# ARMv8M-Baseline register map
Registers are read-only, no defined reset value unless marked. A register's access mark holds for its fields unless they carry their own. Offsets are from the block's base; [hi:lo] are bit positions; {n}, {i} and the like mark numbered series.

## DIB — Debug Identification Block
Base 0xE000EFB0
0x00 DLAR wo — SCS Software Lock Access Register provides CoreSight Software Lock control for the SCS, see the CoreSight Architecture Specification for details
  [31:0] KEY — Lock Access control
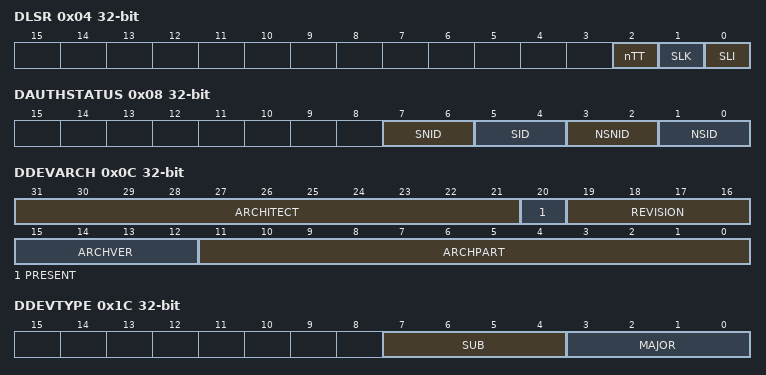
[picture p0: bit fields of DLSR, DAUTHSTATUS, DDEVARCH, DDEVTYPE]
0x04 DLSR — SCS Software Lock Status Register provides CoreSight Software Lock status information for the SCS, see the CoreSight Architecture Specification for details
  [2] nTT — Not thirty-two bit. See the CoreSight Architecture Specification
  [1] SLK — Software Lock status. See the CoreSight Architecture Specification
    0=Lock clear. Software writes are permitted to this component's registers; 1=Lock set
  [0] SLI — Software Lock implemented. See the CoreSight Architecture Specification
    0=Software Lock not implemented or debugger access; 1=Software Lock is implemented and software access
0x08 DAUTHSTATUS — Debug Authentication Status Register provides information about the state of the IMPLEMENTATION DEFINED authentication interface for debug
  [7:6] SNID — Secure Non-invasive Debug. Indicates whether Secure non-invasive debug is allowed
    0=Security Extension not implemented; 2=Security Extension implemented and Secure non-invasive debug prohibited; 3=Security Extension implemented and Secure non-invasive debug allowed
  [5:4] SID — Secure Invasive Debug. Indicates whether Secure invasive debug is allowed
    0=Security Extension not implemented; 2=Security Extension implemented and Secure invasive debug prohibited; 3=Security Extension implemented and Secure invasive debug allowed
  [3:2] NSNID — Non-secure Non-invasive Debug. Indicates whether Non-secure non-invasive debug is allowed
  [1:0] NSID — Non-secure Invasive Debug. Indicates whether Non-secure invasive debug is allowed
0x0C DDEVARCH — SCS Device Architecture Register provides CoreSight discovery information for the SCS
  [31:21] ARCHITECT — Architect. Defines the architect of the component
    0x23B=JEP106 continuation code 0x4, ID code 0x3B. ARM Limited
  [20] PRESENT — DEVARCH Present. Defines that the DEVARCH register is present
    1=DEVARCH information present
  [19:16] REVISION — Revision. Defines the architecture revision of the component
    0=M-profile debug architecture v3.0
  [15:12] ARCHVER — Architecture Version. Defines the architecture version of the component
    2=M-profile debug architecture v3
  [11:0] ARCHPART — Architecture Part. Defines the architecture of the component
    0xA04=M-profile debug architecture
0x1C DDEVTYPE — SCS Device Type Register provides CoreSight discovery information for the SCS
  [7:4] SUB — Subtype. Component subtype
    0=Other
  [3:0] MAJOR — Major type. CoreSight major type
    0=Miscellaneous
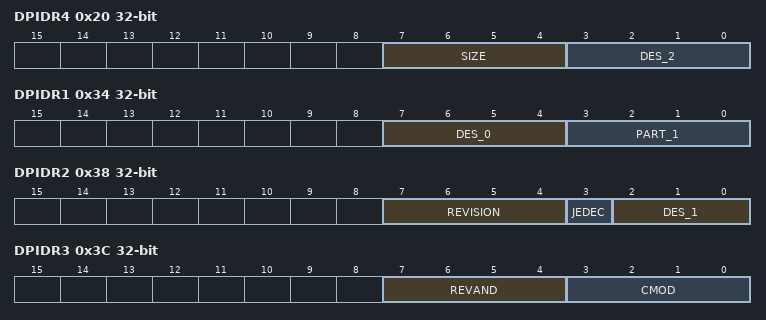
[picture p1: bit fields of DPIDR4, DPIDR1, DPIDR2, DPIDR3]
0x20 DPIDR4 — SCS Peripheral Identification Register 4 provides CoreSight discovery information for the SCS
  [7:4] SIZE — 4KB count. See the CoreSight Architecture Specification
  [3:0] DES_2 — JEP106 continuation code. See the CoreSight Architecture Specification
{0x10+4i} DPIDR{i} (i=5..7) — SCS Peripheral Identification Register {i} provides CoreSight discovery information for the SCS
0x30 DPIDR0 — SCS Peripheral Identification Register 0 provides CoreSight discovery information for the SCS
  [7:0] PART_0 — Part number bits [7:0]. See the CoreSight Architecture Specification
0x34 DPIDR1 — SCS Peripheral Identification Register 1 provides CoreSight discovery information for the SCS
  [7:4] DES_0 — JEP106 identification code bits [3:0]. See the CoreSight Architecture Specification
  [3:0] PART_1 — Part number bits [11:8]. See the CoreSight Architecture Specification
0x38 DPIDR2 — SCS Peripheral Identification Register 2 provides CoreSight discovery information for the SCS
  [7:4] REVISION — Component revision. See the CoreSight Architecture Specification
  [3] JEDEC — JEDEC assignee value is used. See the CoreSight Architecture Specification
  [2:0] DES_1 — JEP106 identification code bits [6:4]. See the CoreSight Architecture Specification
0x3C DPIDR3 — SCS Peripheral Identification Register 3 provides CoreSight discovery information for the SCS
  [7:4] REVAND — RevAnd. See the CoreSight Architecture Specification
  [3:0] CMOD — Customer Modified. See the CoreSight Architecture Specification
0x40 DCIDR0 — SCS Component Identification Register 0 provides CoreSight discovery information for the SCS
  [7:0] PRMBL_0 — CoreSight component identification preamble
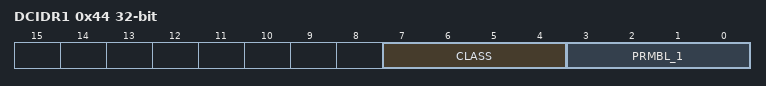
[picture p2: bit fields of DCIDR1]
0x44 DCIDR1 — SCS Component Identification Register 1 provides CoreSight discovery information for the SCS
  [7:4] CLASS — CoreSight component class. See the CoreSight Architecture Specification
  [3:0] PRMBL_1 — CoreSight component identification preamble
0x48 DCIDR2 — SCS Component Identification Register 2 provides CoreSight discovery information for the SCS
  [7:0] PRMBL_2 — CoreSight component identification preamble
0x4C DCIDR3 — SCS Component Identification Register 3 provides CoreSight discovery information for the SCS
  [7:0] PRMBL_3 — CoreSight component identification preamble
